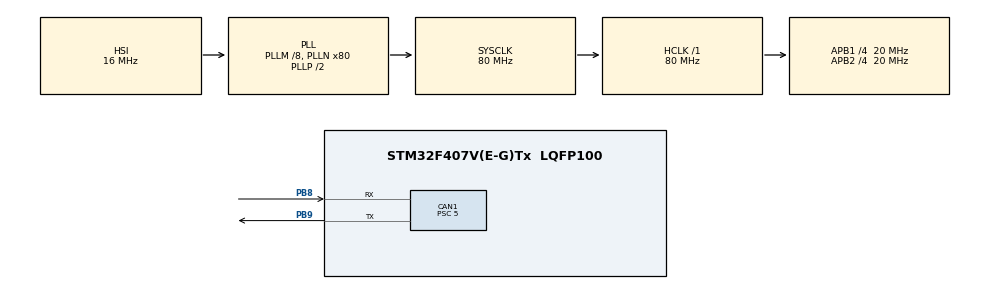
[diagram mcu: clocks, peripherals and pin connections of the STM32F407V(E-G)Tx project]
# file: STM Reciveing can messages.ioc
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CAN1.BS1=CAN_BS1_2TQ
CAN1.BS2=CAN_BS2_1TQ
CAN1.CalculateBaudRate=1000000
CAN1.CalculateTimeBit=1000
CAN1.CalculateTimeQuantum=250.0
CAN1.Prescaler=5
Mcu.Family=STM32F4
Mcu.Name=STM32F407V(E-G)Tx
Mcu.Package=LQFP100
NVIC.CAN1_RX0_IRQn=true\:0\:0\:false\:false\:true\:true\:true
NVIC.PriorityGroup=NVIC_PRIORITYGROUP_4
NVIC.TIM1_UP_TIM10_IRQn=true\:15\:0\:false\:false\:true\:false\:true
NVIC.TimeBase=TIM1_UP_TIM10_IRQn
NVIC.TimeBaseIP=TIM1
PB8.Mode=CAN_Activate
PB8.Signal=CAN1_RX
PB9.Mode=CAN_Activate
PB9.Signal=CAN1_TX
ProjectManager.HeapSize=0x200
ProjectManager.StackSize=0x400
ProjectManager.TargetToolchain=STM32CubeIDE
RCC.48MHZClocksFreq_Value=40000000
RCC.AHBFreq_Value=80000000
RCC.APB1CLKDivider=RCC_HCLK_DIV4
RCC.APB1Freq_Value=20000000
RCC.APB1TimFreq_Value=40000000
RCC.APB2CLKDivider=RCC_HCLK_DIV4
RCC.APB2Freq_Value=20000000
RCC.APB2TimFreq_Value=40000000
RCC.CortexFreq_Value=80000000
RCC.HCLKFreq_Value=80000000
RCC.HSE_VALUE=25000000
RCC.HSI_VALUE=16000000
RCC.LSE_VALUE=32768
RCC.PLLM=8
RCC.PLLN=80
RCC.SYSCLKFreq_VALUE=80000000
RCC.SYSCLKSource=RCC_SYSCLKSOURCE_PLLCLK
RCC.VCOOutputFreq_Value=160000000
VP_SYS_VS_tim1.Mode=TIM1
board=custom

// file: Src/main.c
/* USER CODE BEGIN Header */
/**
  ******************************************************************************
  * @file           : main.c
  * @brief          : Main program body
  ******************************************************************************
  * @attention
  *
  * <h2><center>&copy; Copyright (c) 2021 STMicroelectronics.
  * All rights reserved.</center></h2>
  *
  * This software component is licensed by ST under BSD 3-Clause license,
  * the "License"; You may not use this file except in compliance with the
  * License. You may obtain a copy of the License at:
  *                        opensource.org/licenses/BSD-3-Clause
  *
  ******************************************************************************
  */

/*
 * This code written by Mahmoud Sharabati
 * This code is for testing the STM32F407VG CAN1 channel
 * The STM32 pins are PB8 and PB9
 * The CAN Bit rate is 1 Mbit/s
 * To modifiy the CAN configuration --> change the values on the while(1)
 * /
 */
/* USER CODE END Header */
#include "main.h"

CAN_HandleTypeDef hcan1;

/* USER CODE BEGIN PV */
CAN_FilterTypeDef sFilterConfig;
CAN_TxHeaderTypeDef TxHeader;

/* USER CODE END PV */

void SystemClock_Config(void);
static void MX_GPIO_Init(void);
static void MX_CAN1_Init(void);
/* USER CODE BEGIN PFP */
void run_motor(void);
/* USER CODE END PFP */

int main(void)
{

  /* MCU Configuration--------------------------------------------------------*/

  /* Reset of all peripherals, Initializes the Flash interface and the Systick. */
  HAL_Init();

  /* Configure the system clock */
  SystemClock_Config();

  /* Initialize all configured peripherals */
  MX_GPIO_Init();
  MX_CAN1_Init();
  /* USER CODE BEGIN 2 */

	sFilterConfig.FilterBank = 0;
	sFilterConfig.FilterMode = CAN_FILTERMODE_IDMASK;
	sFilterConfig.FilterScale = CAN_FILTERSCALE_32BIT;
	sFilterConfig.FilterIdHigh = 0x0000;
	sFilterConfig.FilterIdLow = 0x0000;
	sFilterConfig.FilterMaskIdHigh = 0x0000;
	sFilterConfig.FilterMaskIdLow = 0x0000;
	sFilterConfig.FilterFIFOAssignment = CAN_RX_FIFO0;
	sFilterConfig.FilterActivation = ENABLE;
	sFilterConfig.SlaveStartFilterBank = 14;

if (HAL_CAN_ConfigFilter(&hcan1, &sFilterConfig) != HAL_OK)
{
/* Filter configuration Error */
Error_Handler();
}

if(HAL_CAN_Start(&hcan1)!= HAL_OK)
	{
	Error_Handler();
	}
if(HAL_CAN_ActivateNotification(&hcan1,CAN_IT_RX_FIFO0_MSG_PENDING | CAN_IT_TX_MAILBOX_EMPTY) != HAL_OK)
	{

	Error_Handler();
	HAL_GPIO_WritePin(GPIOD, GPIO_PIN_13, GPIO_PIN_SET);

	}

  /* USER CODE END 2 */

  /* Infinite loop */
  while (1)
  {

    /* USER CODE BEGIN 3 */
		uint8_t TxData[8]= {0xFF, 0xAA, 0xBB, 0xAB, 0x3F, 0x13, 0x55, 0xCD};
		/* Start Transmitting the Door Status */
			uint32_t TxMailbox;
			TxHeader.StdId = 0x321;
			TxHeader.ExtId = 0xABC;
			TxHeader.RTR = CAN_RTR_DATA;
			TxHeader.IDE = CAN_ID_EXT;
			TxHeader.DLC = 8;
			TxHeader.TransmitGlobalTime = DISABLE;

		while(1){
		HAL_CAN_AddTxMessage(&hcan1, &TxHeader, TxData, &TxMailbox);
		HAL_Delay(100);}
  }
  /* USER CODE END 3 */
}

void SystemClock_Config(void)
{
  RCC_OscInitTypeDef RCC_OscInitStruct = {0};
  RCC_ClkInitTypeDef RCC_ClkInitStruct = {0};

  /** Configure the main internal regulator output voltage
  */
  __HAL_RCC_PWR_CLK_ENABLE();
  __HAL_PWR_VOLTAGESCALING_CONFIG(PWR_REGULATOR_VOLTAGE_SCALE1);
  /** Initializes the RCC Oscillators according to the specified parameters
  * in the RCC_OscInitTypeDef structure.
  */
  RCC_OscInitStruct.OscillatorType = RCC_OSCILLATORTYPE_HSI;
  RCC_OscInitStruct.HSIState = RCC_HSI_ON;
  RCC_OscInitStruct.HSICalibrationValue = RCC_HSICALIBRATION_DEFAULT;
  RCC_OscInitStruct.PLL.PLLState = RCC_PLL_ON;
  RCC_OscInitStruct.PLL.PLLSource = RCC_PLLSOURCE_HSI;
  RCC_OscInitStruct.PLL.PLLM = 8;
  RCC_OscInitStruct.PLL.PLLN = 80;
  RCC_OscInitStruct.PLL.PLLP = RCC_PLLP_DIV2;
  RCC_OscInitStruct.PLL.PLLQ = 4;
  if (HAL_RCC_OscConfig(&RCC_OscInitStruct) != HAL_OK)
  {
    Error_Handler();
  }
  /** Initializes the CPU, AHB and APB buses clocks
  */
  RCC_ClkInitStruct.ClockType = RCC_CLOCKTYPE_HCLK|RCC_CLOCKTYPE_SYSCLK
                              |RCC_CLOCKTYPE_PCLK1|RCC_CLOCKTYPE_PCLK2;
  RCC_ClkInitStruct.SYSCLKSource = RCC_SYSCLKSOURCE_PLLCLK;
  RCC_ClkInitStruct.AHBCLKDivider = RCC_SYSCLK_DIV1;
  RCC_ClkInitStruct.APB1CLKDivider = RCC_HCLK_DIV4;
  RCC_ClkInitStruct.APB2CLKDivider = RCC_HCLK_DIV4;

  if (HAL_RCC_ClockConfig(&RCC_ClkInitStruct, FLASH_LATENCY_2) != HAL_OK)
  {
    Error_Handler();
  }
}

static void MX_CAN1_Init(void)
{

  hcan1.Instance = CAN1;
  hcan1.Init.Prescaler = 5;
  hcan1.Init.Mode = CAN_MODE_NORMAL;
  hcan1.Init.SyncJumpWidth = CAN_SJW_1TQ;
  hcan1.Init.TimeSeg1 = CAN_BS1_2TQ;
  hcan1.Init.TimeSeg2 = CAN_BS2_1TQ;
  hcan1.Init.TimeTriggeredMode = DISABLE;
  hcan1.Init.AutoBusOff = DISABLE;
  hcan1.Init.AutoWakeUp = DISABLE;
  hcan1.Init.AutoRetransmission = DISABLE;
  hcan1.Init.ReceiveFifoLocked = DISABLE;
  hcan1.Init.TransmitFifoPriority = DISABLE;
  if (HAL_CAN_Init(&hcan1) != HAL_OK)
  {
    Error_Handler();
  }

}

static void MX_GPIO_Init(void)
{

  /* GPIO Ports Clock Enable */
  __HAL_RCC_GPIOB_CLK_ENABLE();

}

void HAL_TIM_PeriodElapsedCallback(TIM_HandleTypeDef *htim)
{
  if (htim->Instance == TIM1) {
    HAL_IncTick();
  }
}

void Error_Handler(void)
{
  __disable_irq();
  while (1)
  {
  }
}
